# TESTCHIP register map
Registers are 32-bit, read-write, reset 0x0 unless marked. A register's access mark holds for its fields unless they carry their own. Offsets are from the block's base; lines under a group give offsets from that group; [hi:lo] are bit positions; {n}, {i} and the like mark numbered series; 'fields as' and 'values as' point back to an identical list; <NAME> marks a mode.

## Memory map
0x40020000 GPIOA — General purpose I/O port A
0x40020400 GPIOB

## GPIOA — General purpose I/O port A
Base 0x40020000
Same registers: GPIOB 0x40020400
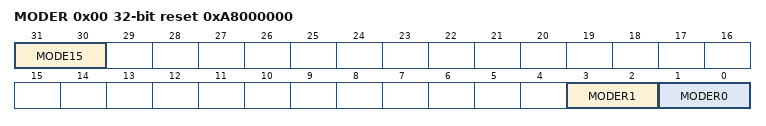
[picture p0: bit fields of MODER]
0x00 MODER reset 0xA8000000 — Mode register
  [31:30] MODE15
    0=Input; 1=Output; 2=Alternate; 3=Analog
  [2n+1:2n] MODER{n} (n=0..1)
0x10 IDR ro
  [0] IDR0
0x20 AFR[{x}] (x=L,H; step 0x4)
{0x40+0x10*i} CH{i} (i=0..1) group
  0x00 CTRL 16-bit
